AUTOSAR XML (schema 4-2-2)
package /ComponentTypes
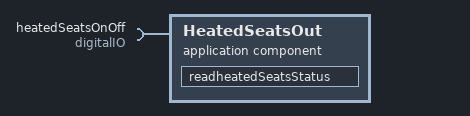
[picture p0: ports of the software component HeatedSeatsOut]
  application sw component type HeatedSeatsOut
    require port heatedSeatsOnOff: nonqueued-receiver-com-spec{data-element=boolean, init-value=0}, required-interface=digitalIO
    behavior HeatedSeatsOut_InternalBehavior
      data received event DRT_readWriteheatedSeats_heatedSeatsOnOff_boolean: start-on-event=readheatedSeatsStatus, data=heatedSeatsOnOff.boolean
      runnable readheatedSeatsStatus
        data-receive-point-by-arguments:
          access REC_heatedSeatsOnOff_boolean: accessed-variable=heatedSeatsOnOff.boolean
  swc implementation HeatedSeatsOut_Implementation: behavior=HeatedSeatsOut_InternalBehavior
